VERSION ""

BO_ 800 SPEED_UNKOWN: 8 off
 SG_ SPEED_UN : 0|12@1+ (0.1,0) [0|255] "kph" EON
BO_ 801 UNKOWN2: 8 off
BO_ 547 FAST1BOTH: 8 off

BO_ 877 FAST2: 8 off
BO_ 291 FAST3BOTH: 8 off
BO_ 536 FAST4_PARK_BOTH: 8 off 0002, release A102, A002, lock, A104-8806, 0806, 9204 8806
BO_ 1143 FAST5: 8 off
BO_ 1097 FAST6: 8 off
BO_ 1089 FAST9: 8 off
BO_ 1092 FAST7: 8 off
BO_ 1093 SLOW1: 8 off
BO_ 1101 MOVE1: 8 off
BO_ 836 SLOW2: 8 off
BO_ 833 FAST8BOTH: 8 off  D(F1 A9 00 ---- 38) P (F19500  4C),  move FA1901---- 37
BO_ 140 FAST10: 8 off

BO_ 289 ENGINE_DATA: 8 ECM
 SG_ XMISSION_SPEED : 0|12@1+ (0.08,0) [0|255] "" EON

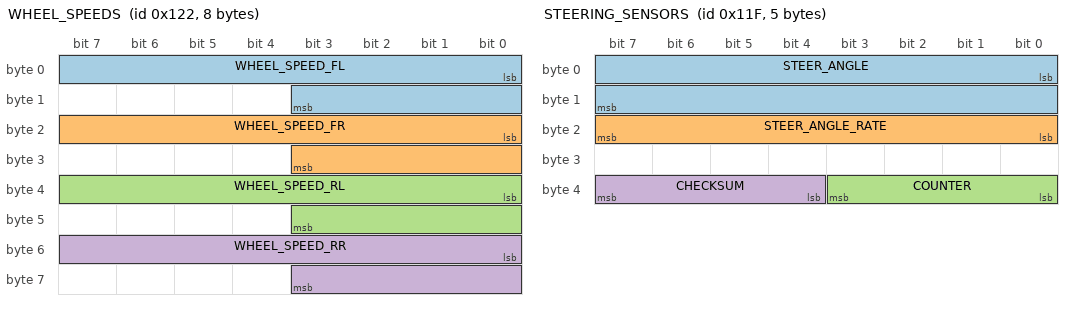
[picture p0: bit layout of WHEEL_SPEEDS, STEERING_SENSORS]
BO_ 290 WHEEL_SPEEDS: 8 ECM
 SG_ WHEEL_SPEED_FL : 0|12@1+ (0.08,0) [0|255] "" ECM
 SG_ WHEEL_SPEED_FR : 16|12@1+ (0.08,0) [0|255] "" ECM
 SG_ WHEEL_SPEED_RL : 32|12@1+ (0.08,0) [0|255] "" ECM
 SG_ WHEEL_SPEED_RR : 48|12@1+ (0.08,0) [0|255] "" ECM

BO_ 835 CRUISE: 8 ECM
 SG_ SET_ME : 31|4@0+ (1,0) [0|255] "" ECM
VAL_ 835 SET_ME 9 "OFF" 11 "ON"

BO_ 491 WIPER: 8 ECM
 SG_ WIPE : 3|4@0+ (1,0) [0|255] "" ECM
VAL_ 491 WIPE 9 "HOLD" 5 "MOVE"

BO_ 307 LIGHT2: 8 ECM
 SG_ BLINK : 5|2@0+ (1,0) [0|255] "" ECM
 SG_ LEFT_BLINKER : 4|1@0+ (1,0) [0|255] "" ECM
 SG_ RIGHT_BLINKER : 5|1@0+ (1,0) [0|255] "" ECM
 SG_ FOGLIGHT : 7|2@0+ (1,0) [0|255] "" ECM
 SG_ LIGHT2 : 3|4@0+ (1,0) [0|255] "" ECM
 SG_ COUNTER : 63|4@0+ (1,0) [0|255] "" ECM
VAL_ 307 LIGHT2 0 "OFF" 2 "light1" 6 "light" 14 "long light";
VAL_ 307 BLINK 1 "LEFT" 2 "RIGHT"
VAL_ 307 FOGLIGHT 0 "OFF" 1 "FRONT" 2 "REAR" 3 "BOTH"

BO_ 287 STEERING_SENSORS: 5 EPS
 SG_ STEER_ANGLE : 0|16@1- (0.1,0) [-650|650] "deg" EON
 SG_ STEER_ANGLE_RATE : 16|8@1- (1,0) [-650|650] "deg/s" EON
 SG_ COUNTER : 32|4@1+ (1,0) [0|255] "" EON
 SG_ CHECKSUM : 36|4@1+ (1,0) [0|255] "" EON
BO_ 523 LIGHT: 8 BDY
 SG_ LIGHT : 24|4@1+ (1,0) [0|16] "" EON
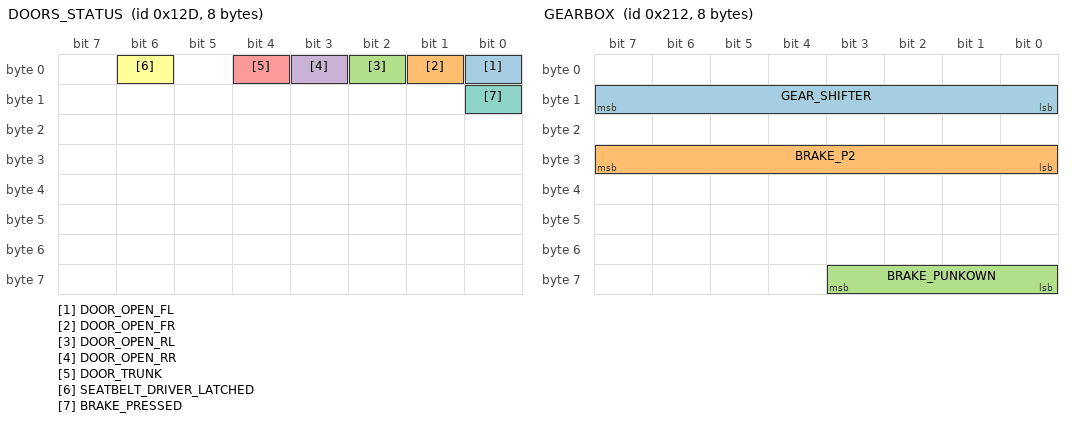
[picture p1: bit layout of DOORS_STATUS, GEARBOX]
BO_ 301 DOORS_STATUS: 8 BDY
 SG_ DOOR_OPEN_FL : 0|1@0+ (1,0) [0|1] "" EON
 SG_ DOOR_OPEN_FR : 1|1@0+ (1,0) [0|1] "" EON
 SG_ DOOR_OPEN_RL : 2|1@0+ (1,0) [0|1] "" EON
 SG_ DOOR_OPEN_RR : 3|1@0+ (1,0) [0|1] "" EON
 SG_ DOOR_TRUNK : 4|1@0+ (1,0) [0|1] "" EON
 SG_ SEATBELT_DRIVER_LATCHED : 6|1@0+ (1,0) [0|1] "" EON
 SG_ BRAKE_PRESSED : 8|1@0+ (1,0) [0|1] "" EON
BO_ 578 SPEED_STATUS: 8 BDY
 SG_ SPEED : 0|16@1+ (0.017,-510) [0|255] "" EON
BO_ 530 GEARBOX: 8 BDY
 SG_ GEAR_SHIFTER : 15|8@0+ (1,0) [0|255] "" EON
 SG_ BRAKE_P2 : 31|8@0+ (1,0) [0|255] "" EON
 SG_ BRAKE_PUNKOWN : 59|4@0+ (1,0) [0|255] "" EON

BO_ 269 POWERTRAIN: 8 BDY
 SG_ BRAKE_P3 : 55|16@0+ (1,0) [67|71] "" EON  75 half
 SG_ ENGINE_RPM_UNKNOWN : 0|16@1- (0.25,0) [0|255] "" EON
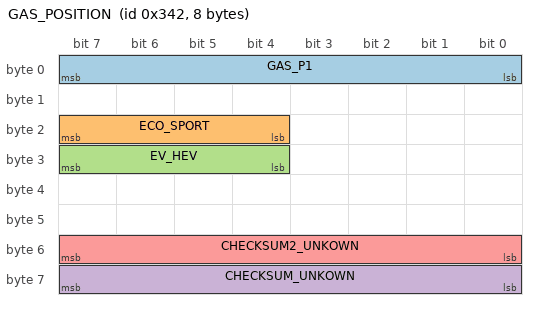
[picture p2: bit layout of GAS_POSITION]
BO_ 834 GAS_POSITION: 8 BDY
 SG_ GAS_P1 : 7|8@0+ (1,0) [0|255] "" EON
 SG_ ECO_SPORT : 20|4@1+ (1,0) [0|255] "" EON
 SG_ EV_HEV : 28|4@1+ (1,0) [0|255] "" EON
 SG_ CHECKSUM_UNKOWN : 56|8@1+ (1,0) [0|255] "" EON
 SG_ CHECKSUM2_UNKOWN : 48|8@1+ (1,0) [0|255] "" EON

BO_ 548 BRAKE_POSITION: 8 BDY
 SG_ BRAKE_P4 : 32|16@1+ (1,0) [0|255] "" EON   9C-BC
 SG_ CHECKSUM5_UNKOWN : 56|8@1+ (1,0) [0|255] "" EON
 SG_ CHECKSUM6_UNKOWN : 48|8@1+ (1,0) [0|255] "" EON
 SG_ COUNTER22 : 52|4@1+ (1,0) [0|255] "" EON
 SG_ COUNTER12 : 60|4@1+ (1,0) [0|255] "" EON

BO_ 549 BRAKE_POSITION2: 8 BDY
 SG_ BRAKE_P5 : 24|16@1+ (1,0) [0|255] "" EON
 SG_ CHECKSUM3_UNKOWN : 56|8@1+ (1,0) [0|255] "" EON
 SG_ CHECKSUM4_UNKOWN : 48|8@1+ (1,0) [0|255] "" EON
 SG_ COUNTER2 : 52|4@1+ (1,0) [0|255] "" EON
 SG_ COUNTER : 60|4@1+ (1,0) [0|255] "" EON

BO_ 860 GEAR2_CONTROL: 8 BDY
 SG_ GEAR2 : 15|8@0+ (1,0) [0|255] "" EON
BO_ 665 STEERING_KEY: 8 EPS
 SG_ STEER_KEY : 20|4@1- (1,0) [0|255] "" EON
VAL_ 530 GEAR_SHIFTER 4 "D" 3 "N" 2 "R" 1 "P" ;
VAL_ 530 BRAKE_P2 8 "release" 12 "press" ;
VAL_ 530 BRAKE_P4 4 "release" 0 "press" ;
VAL_ 860 GEAR2 4 "D" 3 "N" 2 "R" 1 "P" ;
VAL_ 269 BRAKE_P3 67 "release" 71 "press" 75 "half" ;
VAL_ 834 ECO_SPORT 2 "sport" 1 "eco" ;
VAL_ 834 EV_HEV 9 "EV" 11 "HEV" ;
VAL_ 523 LIGHT 15 "OFF" 12 "AUTO" 9 "AUTO" 7 "NIGHT" 6 "LONG" 4 "LONG" 5 "LONG" ;
VAL_ 665 STEER_KEY 6 "LEFT" 7 "RIGHT"
